# YTM32B1HA0 register map
Vendor: YTMicro; File version: 1.0
CPU: little endian, MPU, FPU, 2 interrupt priority bits
Registers are 32-bit, read-write, reset 0x0 unless marked. A register's access mark holds for its fields unless they carry their own. Offsets are from the block's base; [hi:lo] are bit positions; {n}, {i} and the like mark numbered series; 'fields as' and 'values as' point back to an identical list.

## ENET (part 9 of 10) — Ethernet Quality-of-Service
Base 0x401E4000; register names take the prefix ENET_
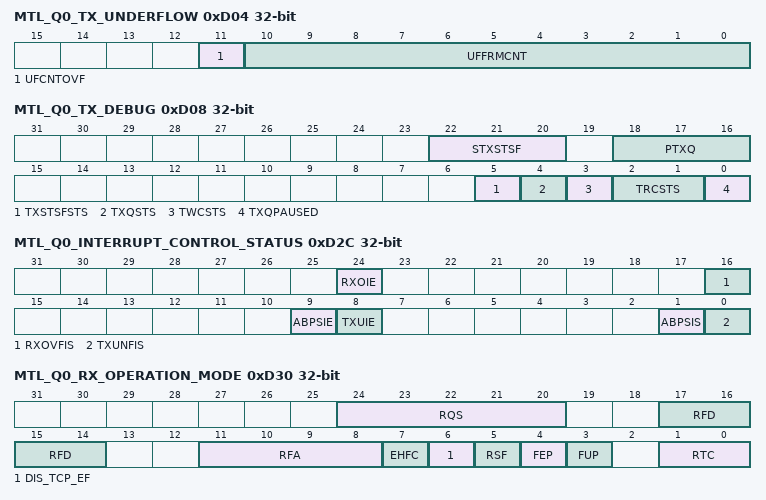
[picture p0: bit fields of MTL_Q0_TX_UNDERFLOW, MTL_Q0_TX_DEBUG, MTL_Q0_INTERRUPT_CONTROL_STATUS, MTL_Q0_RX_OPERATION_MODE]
0xD04 MTL_Q0_TX_UNDERFLOW — The Queue 0 Underflow Counter register contains the counter for packets aborted because of Transmit queue underflow and packets missed because of Receive queue packet flush
  [11] UFCNTOVF — This bit is set every time the Tx queue Underflow Packet Counter field overflows, that is, it has crossed the maximum count. In such a scenario, the overflow packet counter is reset to all-zeros and this bit indicates that the rollover happened. Access restriction applies. Clears on read. Self-set to 1 on internal event.
    0=Overflow not detected for Underflow Packet Counter; 1=Overflow detected for Underflow Packet Counter
  [10:0] UFFRMCNT — This field indicates the number of packets aborted by the controller because of Tx Queue Underflow. This counter is incremented each time the MAC aborts outgoing packet because of underflow. The counter is cleared when this register is read with mci_be_i[0] at 1'b1. Access restriction applies. Clears on read. Self-set to 1 on internal event.
0xD08 MTL_Q0_TX_DEBUG — The Queue 0 Transmit Debug register gives the debug status of various blocks related to the Transmit queue.
  [22:20] STXSTSF — This field indicates the current number of status in the Tx Status FIFO of this queue. When the DTXSTS bit of MTL_Operation_Mode register is set to 1, this field does not reflect the number of status words in Tx Status FIFO.
  [18:16] PTXQ — This field indicates the current number of packets in the Tx Queue. When the DTXSTS bit of MTL_Operation_Mode register is set to 1, this field does not reflect the number of packets in the Transmit queue.
  [5] TXSTSFSTS — When high, this bit indicates that the MTL Tx Status FIFO is full. Therefore, the MTL cannot accept any more packets for transmission.
    0=MTL Tx Status FIFO Full status is not detected; 1=MTL Tx Status FIFO Full status is detected
  [4] TXQSTS — When this bit is high, it indicates that the MTL Tx Queue is not empty and some data is left for transmission.
    0=MTL Tx Queue Not Empty status is not detected; 1=MTL Tx Queue Not Empty status is detected
  [3] TWCSTS — When high, this bit indicates that the MTL Tx Queue Write Controller is active, and it is transferring the data to the Tx Queue.
    0=MTL Tx Queue Write Controller status is not detected; 1=MTL Tx Queue Write Controller status is detected
  [2:1] TRCSTS — This field indicates the state of the Tx Queue Read Controller:
    0=Idle state; 1=Read state (transferring data to the MAC transmitter); 2=Waiting for pending Tx Status from the MAC transmitter; 3=Flushing the Tx queue because of the Packet Abort request from the MAC
  [0] TXQPAUSED — When this bit is high and the Rx flow control is enabled, it indicates that the Tx Queue is in the Pause condition (in the full-duplex only mode) because of the following: ■ Reception of the PFC packet for the priorities assigned to the Tx Queue when PFC is enabled ■ Reception of 802.3x Pause packet when PFC is disabled
    0=Transmit Queue in Pause status is not detected; 1=Transmit Queue in Pause status is detected
0xD14 MTL_Q0_TX_ETS_STATUS ro — The Queue n ETS Status register provides the average traffic transmitted in Queue n.
  [23:0] ABS rw — This field contains the average transmitted bits per slot. When the DCB operation is enabled for Queue 0, this field is computed over every 10 million bit times slot (4 ms in 2500 Mbps; 10 ms in 1000 Mbps; 100 ms in 100 Mbps). The maximum value is 0x989680.
0xD18 MTL_Q0_TX_QUANTUM_WEIGHT — The Queue n Quantum or Weights register contains the quantum value for Deficit Weighted Round Robin (DWRR), weights for the Weighted Round Robin (WRR), and Weighted Fair Queuing (WFQ) for Queue n.
  [20:0] ISCQW — When the DCB operation is enabled with DWRR algorithm for Queue 0 traffic, this field contains the quantum value in bytes to be added to credit during every queue scanning cycle. The maximum value is 0x1312D0 bytes. When DCB operation is enabled with WFQ algorithm for Queue 0 traffic, this field contains the weight for this queue. The maximum value is 0x3FFF where weight of 0 indicates 100% bandwidth. Bits[20:14] must be written to zero. The higher the programmed weights lesser the bandwidth allocated for the particular Transmit Queue. This is because the weights are used to compute the packet finish time (weights*packet_size). Lesser the finish time, higher the probability of the packet getting scheduled first and using more bandwidth. When DCB operation or generic queuing operation is enabled with WRR algorithm for Queue 0 traffic, this field contains the weight for this queue. The maximum value is 0x64. Bits [20:7] must be written to zero.
0xD2C MTL_Q0_INTERRUPT_CONTROL_STATUS — This register contains the interrupt enable and status bits for the queue 0 interrupts.
  [24] RXOIE — When this bit is set, the Receive Queue Overflow interrupt is enabled. When this bit is reset, the Receive Queue Overflow interrupt is disabled.
    0=Receive Queue Overflow Interrupt is disabled; 1=Receive Queue Overflow Interrupt is enabled
  [16] RXOVFIS — This bit indicates that the Receive Queue had an overflow while receiving the packet. If a partial packet is transferred to the application, the overflow status is set in RDES3[21]. This bit is cleared when the application writes 1 to this bit. Access restriction applies. Self-set to 1 on internal event. Setting 1 clears. Setting 0 has no effect.
    0=Receive Queue Overflow Interrupt Status not detected; 1=Receive Queue Overflow Interrupt Status detected
  [9] ABPSIE — When this bit is set, the MAC asserts the sbd_intr_o or mci_intr_o interrupt when the average bits per slot status is updated. When this bit is cleared, the interrupt is not asserted for such an event.
    0=Average Bits Per Slot Interrupt is disabled; 1=Average Bits Per Slot Interrupt is enabled
  [8] TXUIE — When this bit is set, the Transmit Queue Underflow interrupt is enabled. When this bit is reset, the Transmit Queue Underflow interrupt is disabled.
    0=Transmit Queue Underflow Interrupt Status is disabled; 1=Transmit Queue Underflow Interrupt Status is enabled
  [1] ABPSIS — When set, this bit indicates that the MAC has updated the ABS value. This bit is cleared when the application writes 1 to this bit. Access restriction applies. Self-set to 1 on internal event. Setting 1 clears. Setting 0 has no effect.
    0=Average Bits Per Slot Interrupt Status not detected; 1=Average Bits Per Slot Interrupt Status detected
  [0] TXUNFIS — This bit indicates that the Transmit Queue had an underflow while transmitting the packet. Transmission is suspended and an Underflow Error TDES3[2] is set. This bit is cleared when the application writes 1 to this bit. Access restriction applies. Self-set to 1 on internal event. Setting 1 clears. Setting 0 has no effect.
    0=Transmit Queue Underflow Interrupt Status not detected; 1=Transmit Queue Underflow Interrupt Status detected
0xD30 MTL_Q0_RX_OPERATION_MODE — The Queue 0 Receive Operation Mode register establishes the Receive queue operating modes and command. The RFA and RFD fields are not backward compatible with the RFA and RFD fields of 4.00a release
  [24:20] RQS — This field indicates the size of the allocated Receive queues in blocks of 256 bytes. The RQS field is read-write only if the number of Rx Queues more than one, the reset value is 0x0 and indicates size of 256 bytes. When the number of Rx Queues is one, the field is read-only and the configured RX FIFO size in blocks of 256 bytes is reflected in the reset value. The width of this field depends on the Rx memory size selected in your configuration. For example, if the memory size is 2048, the width of this field is 3 bits: LOG2(2048/256) = LOG2(8) = 3 bits
  [17:14] RFD — These bits control the threshold (fill-level of Rx queue) at which the flow control is de-asserted after activation: ■ 0: Full minus 1 KB, that is, FULL 1 KB ■ 1: Full minus 1.5 KB, that is, FULL 1.5 KB ■ 2: Full minus 2 KB, that is, FULL 2 KB ■ 3: Full minus 2.5 KB, that is, FULL 2.5 KB ■ ... ■ 62: Full minus 32 KB, that is, FULL 32 KB ■ 63: Full minus 32.5 KB, that is, FULL 32.5 KB The de-assertion is effective only after flow control is asserted. Note: The value must be programmed in such a way to make sure that the threshold is a positive number. When the EHFC is set high, these values are applicable only when the Rx queue size determined by the RQS field of this register, is equal to or greater than 4 KB. For a given queue size, the values ranges between 0 and the encoding for FULL minus (QSIZE - 0.5 KB) and all other values are illegal. Here the term FULL and QSIZE refers to the queue size determined by the RQS field of this register. The width of this field depends on RX FIFO size selected during the configuration. Remaining bits are reserved and read only.
  [11:8] RFA — These bits control the threshold (fill-level of Rx queue) at which the flow control is activated: For more information on encoding for this field, see RFD.
  [7] EHFC — When this bit is set, the flow control signal operation, based on the fill-level of Rx queue, is enabled. When reset, the flow control operation is disabled.
    0=Hardware Flow Control is disabled; 1=Hardware Flow Control is enabled
  [6] DIS_TCP_EF — When this bit is set, the MAC does not drop the packets which only have the errors detected by the Receive Checksum Offload engine. Such packets have errors only in the encapsulated payload. There are no errors (including FCS error) in the Ethernet packet received by the MAC. When this bit is reset, all error packets are dropped if the FEP bit is reset.
    0=Dropping of TCP/IP Checksum Error Packets is enabled; 1=Dropping of TCP/IP Checksum Error Packets is disabled
  [5] RSF — When this bit is set, the DWC_ether_qos reads a packet from the Rx queue only after the complete packet has been written to it, ignoring the RTC field of this register. When this bit is reset, the Rx queue operates in the Threshold (cut-through) mode, subject to the threshold specified by the RTC field of this register.
    0=Receive Queue Store and Forward is disabled; 1=Receive Queue Store and Forward is enabled
  [4] FEP — When this bit is reset, the Rx queue drops packets with error status (CRC error, GMII_ER, watchdog timeout, or overflow). However, if the start byte (write) pointer of a packet is already transferred to the read controller side (in Threshold mode), the packet is not dropped. When this bit is set, all packets except the runt error packets are forwarded to the application or DMA. If the RSF bit is set and the Rx queue overflows when a partial packet is written, the packet is dropped irrespective of the setting of this bit. However, if the RSF bit is reset and the Rx queue overflows when a partial packet is written, a partial packet may be forwarded to the application or DMA.
    0=Forward Error Packets is disabled; 1=Forward Error Packets is enabled
  [3] FUP — When this bit is set, the Rx queue forwards the undersized good packets (packets with no error and length less than 64 bytes), including pad-bytes and CRC. When this bit is reset, the Rx queue drops all packets of less than 64 bytes, unless a packet is already transferred because of the lower value of Rx Threshold, for example, RTC = 01.
    0=Forward Undersized Good Packets is disabled; 1=Forward Undersized Good Packets is enabled
  [1:0] RTC — These bits control the threshold level of the MTL Rx queue (in bytes): The received packet is transferred to the application or DMA when the packet size within the MTL Rx queue is larger than the threshold. In addition, full packets with length less than the threshold are automatically transferred. This field is valid only when the RSF bit is zero. This field is ignored when the RSF bit is set to 1.
    0=64; 1=32; 2=96; 3=128
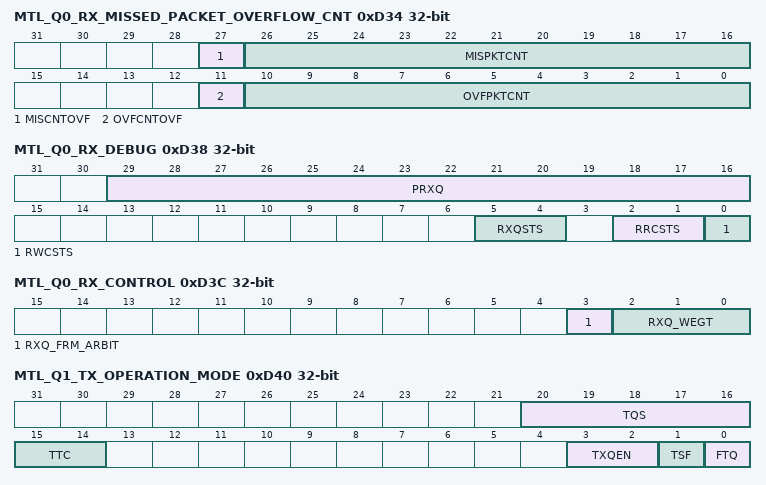
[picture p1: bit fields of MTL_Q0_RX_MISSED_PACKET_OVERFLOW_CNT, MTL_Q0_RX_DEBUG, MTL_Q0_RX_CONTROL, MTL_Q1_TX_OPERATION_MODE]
0xD34 MTL_Q0_RX_MISSED_PACKET_OVERFLOW_CNT — The Queue 0 Missed Packet and Overflow Counter register contains the counter for packets missed because of Receive queue packet flush and packets discarded because of Receive queue overflow.
  [27] MISCNTOVF — When set, this bit indicates that the Rx Queue Missed Packet Counter crossed the maximum limit. Access restriction applies. Clears on read. Self-set to 1 on internal event.
    0=Missed Packet Counter overflow not detected; 1=Missed Packet Counter overflow detected
  [26:16] MISPKTCNT — This field indicates the number of packets missed by the DWC_ether_qos because the application asserted ari_pkt_flush_i[] for this queue. This counter is incremented each time the application issues ari_pkt_flush_i[] for this queue. This counter is reset when this register is read with mci_be_i[0] at 1b1. In EQOS-DMA, EQOS-AXI, and EQOS-AHB configurations, This counter is incremented by 1 when the DMA discards the packet because of buffer unavailability. Access restriction applies. Clears on read. Self-set to 1 on internal event.
  [11] OVFCNTOVF — When set, this bit indicates that the Rx Queue Overflow Packet Counter field crossed the maximum limit. Access restriction applies. Clears on read. Self-set to 1 on internal event.
    0=Overflow Counter overflow not detected; 1=Overflow Counter overflow detected
  [10:0] OVFPKTCNT — This field indicates the number of packets discarded by the DWC_ether_qos because of Receive queue overflow. This counter is incremented each time the DWC_ether_qos discards an incoming packet because of overflow. This counter is reset when this register is read with mci_be_i[0] at 1'b1. Access restriction applies. Clears on read. Self-set to 1 on internal event.
0xD38 MTL_Q0_RX_DEBUG ro — The Queue 0 Receive Debug register gives the debug status of various blocks related to the Receive queue.
  [29:16] PRXQ rw — This field indicates the current number of packets in the Rx Queue. The theoretical maximum value for this field is 256KB/16B = 16K Packets, that is, Max_Queue_Size/Min_Packet_Size.
  [5:4] RXQSTS rw — This field gives the status of the fill-level of the Rx Queue:
    0=Rx Queue empty; 1=Rx Queue fill-level below flow-control deactivate threshold; 2=Rx Queue fill-level above flow-control activate threshold; 3=Rx Queue full
  [2:1] RRCSTS rw — This field gives the state of the Rx queue Read controller:
    0=Idle state; 1=Reading packet data; 2=Reading packet status (or timestamp); 3=Flushing the packet data and status
  [0] RWCSTS rw — When high, this bit indicates that the MTL Rx queue Write controller is active, and it is transferring a received packet to the Rx Queue.
    0=MTL Rx Queue Write Controller Active Status not detected; 1=MTL Rx Queue Write Controller Active Status detected
0xD3C MTL_Q0_RX_CONTROL — The Queue Receive Control register controls the receive arbitration and passing of received packets to the application.
  [3] RXQ_FRM_ARBIT — When this bit is set, the DWC_ether_qos drives the packet data to the ARI interface such that the entire packet data of currently-selected queue is transmitted before switching to other queue. When this bit is reset, the DWC_ether_qos drives the packet data to the ARI interface such that the following amount of data of currently-selected queue is transmitted before switching to other queue: ■ PBL amount of data (indicated by ari_qN_pbl_i[]) or ■ Complete data of a packet The status and the timestamp are not a part of the PBL data. Therefore, the DWC_ether_qos drives the complete status (including timestamp status) during first PBL request for the packet (in store-and-forward mode) or the last PBL request for the packet (in Threshold mode).
    0=Receive Queue Packet Arbitration is disabled; 1=Receive Queue Packet Arbitration is enabled
  [2:0] RXQ_WEGT — This field indicates the weight assigned to the Rx Queue 0. The weight is used as the number of continuous PBL or packets requests (depending on the RXQ_FRM_ARBIT) allocated to the queue in one arbitration cycle.
0xD40 MTL_Q1_TX_OPERATION_MODE — The Queue n Transmit Operation Mode register establishes the Transmit queue operating modes and commands.
  [20:16] TQS — This field indicates the size of the allocated Transmit queues in blocks of 256 bytes. The TQS field is read-write only if the number of Tx Queues more than one, the reset value is 0x0 and indicates size of 256 bytes. When the number of Tx Queues is one, the field is read-only and the configured TX FIFO size in blocks of 256 bytes is reflected in the reset value. The width of this field depends on the Tx memory size selected in your configuration. For example, if the memory size is 2048, the width of this field is 3 bits: LOG2(2048/256) = LOG2(8) = 3 bits
  [15:14] TTC — These bits control the threshold level of the MTL Tx Queue. The transmission starts when the packet size within the MTL Tx Queue is larger than the threshold. In addition, full packets with length less than the threshold are also transmitted. These bits are used only when the TSF bit is reset.
    0=32; 1=64; 2=96; 3=128; 4=192; 5=256; 6=384; 7=512
  [3:2] TXQEN — This field is used to enable/disable the transmit queue 0. ■ 2'b00: Not enabled ■ 2'b01: Reserved ■ 2'b10: Enabled ■ 2'b11: Reserved This field is Read Only in Single Queue configurations and Read Write in Multiple Queue configurations. Note: In multiple Tx queues configuration, all the queues are disabled by default. Enable the Tx queue by programming this field.
    0=Not enabled; 1=Enable in AV mode (Reserved in non-AV); 2=Enabled
  [1] TSF — When this bit is set, the transmission starts when a full packet resides in the MTL Tx queue. When this bit is set, the TTC values specified in Bits[6:4] of this register are ignored. This bit should be changed only when the transmission is stopped.
    0=Transmit Store and Forward is disabled; 1=Transmit Store and Forward is enabled
  [0] FTQ — When this bit is set, the Tx queue controller logic is reset to its default values. Therefore, all the data in the Tx queue is lost or flushed. This bit is internally reset when the flushing operation is complete. Until this bit is reset, you should not write to the MTL_TxQ1_Operation_Mode register. The data which is already accepted by the MAC transmitter is not flushed. It is scheduled for transmission and results in underflow and runt packet transmission. Note: The flush operation is complete only when the Tx queue is empty and the application has accepted the pending Tx Status of all transmitted packets. To complete this flush operation, the PHY Tx clock (clk_tx_i) should be active. Access restriction applies. Setting 1 sets. Self-cleared. Setting 0 has no effect.
    0=Flush Transmit Queue is disabled; 1=Flush Transmit Queue is enabled
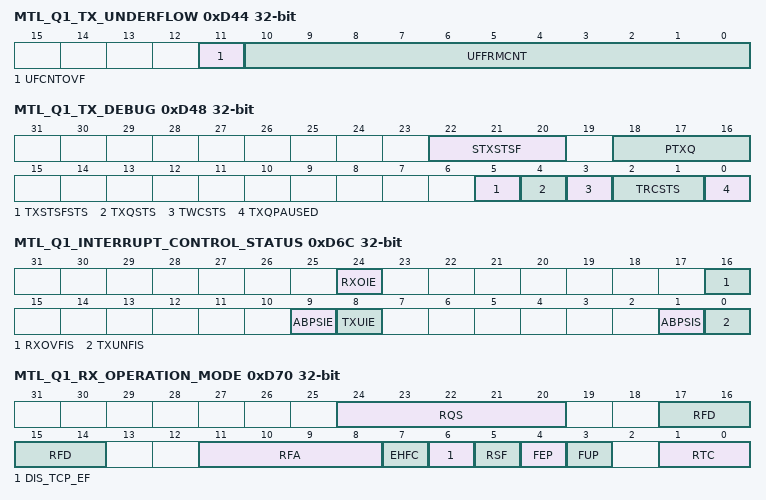
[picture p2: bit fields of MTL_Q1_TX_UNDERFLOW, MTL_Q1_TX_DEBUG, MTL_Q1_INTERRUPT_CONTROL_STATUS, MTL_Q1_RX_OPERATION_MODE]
0xD44 MTL_Q1_TX_UNDERFLOW — The Queue 0 Underflow Counter register contains the counter for packets aborted because of Transmit queue underflow and packets missed because of Receive queue packet flush
  fields as MTL_Q0_TX_UNDERFLOW
0xD48 MTL_Q1_TX_DEBUG — The Queue 0 Transmit Debug register gives the debug status of various blocks related to the Transmit queue.
  fields as MTL_Q0_TX_DEBUG
0xD54 MTL_Q1_TX_ETS_STATUS ro — The Queue n ETS Status register provides the average traffic transmitted in Queue n.
  fields as MTL_Q0_TX_ETS_STATUS
0xD58 MTL_Q1_TX_QUANTUM_WEIGHT — The Queue n Quantum or Weights register contains the quantum value for Deficit Weighted Round Robin (DWRR), weights for the Weighted Round Robin (WRR), and Weighted Fair Queuing (WFQ) for Queue n.
  fields as MTL_Q0_TX_QUANTUM_WEIGHT
0xD6C MTL_Q1_INTERRUPT_CONTROL_STATUS — This register contains the interrupt enable and status bits for the queue 0 interrupts.
  fields as MTL_Q0_INTERRUPT_CONTROL_STATUS
0xD70 MTL_Q1_RX_OPERATION_MODE — The Queue 0 Receive Operation Mode register establishes the Receive queue operating modes and command. The RFA and RFD fields are not backward compatible with the RFA and RFD fields of 4.00a release
  fields as MTL_Q0_RX_OPERATION_MODE
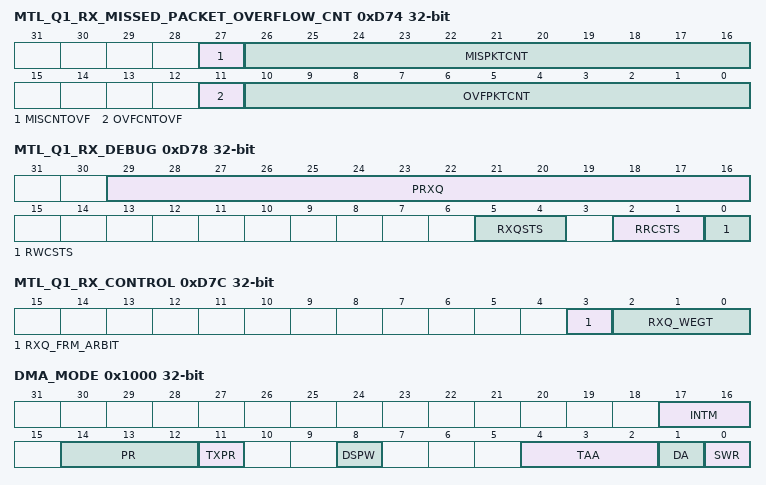
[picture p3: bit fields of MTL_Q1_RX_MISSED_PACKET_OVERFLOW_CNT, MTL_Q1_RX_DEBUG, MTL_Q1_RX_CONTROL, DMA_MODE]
0xD74 MTL_Q1_RX_MISSED_PACKET_OVERFLOW_CNT — The Queue 0 Missed Packet and Overflow Counter register contains the counter for packets missed because of Receive queue packet flush and packets discarded because of Receive queue overflow.
  fields as MTL_Q0_RX_MISSED_PACKET_OVERFLOW_CNT
0xD78 MTL_Q1_RX_DEBUG ro — The Queue 0 Receive Debug register gives the debug status of various blocks related to the Receive queue.
  fields as MTL_Q0_RX_DEBUG
0xD7C MTL_Q1_RX_CONTROL — The Queue Receive Control register controls the receive arbitration and passing of received packets to the application.
  fields as MTL_Q0_RX_CONTROL
0x1000 DMA_MODE — The Bus Mode register establishes the bus operating modes for the DMA.
  [17:16] INTM — This field defines the interrupt mode of DWC_ether_qos. The behavior of the following outputs changes depending on the following settings: ■ sbd_perch_tx_intr_o[] (Transmit Per Channel Interrupt) ■ sbd_perch_rx_intr_o[] (Receive Per Channel Interrupt) ■ sbd_intr_o (Common Interrupt) It also changes the behavior of the RI/TI bits in the DMA_CH0_Status. ■ 00: sbd_perch_* are pulse signals for each TX/RX packet transfer completion events (irrespective of whether corre- sponding interrupts are enabled) for which IOC bits are enabled in descriptor. sbd_intr_o is also asserted when corresponding interrupts are enabled and cleared only when software clears the corresponding RI/TI status bits. ■ 01: sbd_perch_* are level signals asserted on TX/RX packet transfer completion event when corresponding interrupts are enabled and de-asserted when the software clears the corresponding RI/TI status bits. The sbd_intr_o is not asserted for these TX/RX packet transfer completion events. ■ 10: sbd_perch_* are level signals asserted on TX/RX packet transfer completion event when corresponding interrupts are enabled and de-asserted when the software clears the corresponding RI/TI status bits. However, the signal is asserted again if the same event occurred again before it was cleared. The sbd_intr_o is not asserted for these TX/RX packet transfer completion events. ■ 11: Reserved For more details please refer Table "DWC_ether_qos Transfer Complete Interrupt Behavior".
    0=See above description; 1=See above description; 2=See above description
  [14:12] PR — These bits control the priority ratio in weighted round-robin arbitration between the Rx DMA and Tx DMA. These bits are valid only when the DA bit is reset. The priority ratio is Rx:Tx or Tx:Rx depending on whether the TXPR bit is reset or set.
    0=61; 1=121; 2=181; 3=241; 4=301; 5=361; 6=421; 7=481
  [11] TXPR — When set, this bit indicates that the Tx DMA has higher priority than the Rx DMA during arbitration for the system-side bus.
    0=Transmit Priority is disabled; 1=Transmit Priority is enabled
  [8] DSPW — When this bit is set to 0, the descriptor writes are always non-posted. When this bit is set to 1, the descriptor writes are non-posted only when IOC (Interrupt on completion) is set in last descriptor, otherwise the descriptor writes are always posted.
    0=Descriptor Posted Write is disabled; 1=Descriptor Posted Write is enabled
  [4:2] TAA — This field is used to select the arbitration algorithm for the Transmit side when multiple Tx DMAs are selected.
    0=Fixed priority (Channel 0 has the lowest priority and the last channel has the highest priority); 1=Weighted Strict Priority (WSP); 2=Weighted Round Robin (WRR)
  [1] DA — This bit specifies the arbitration scheme between the Transmit and Receive paths of all channels: ■ 0: Weighted Round-Robin with Rx:Tx or Tx:Rx The priority between the paths is according to the priority specified in Bits[14:12] and the priority weight is specified in the TXPR bit. ■ 1: Fixed Priority The Tx path has priority over the Rx path when the TXPR bit is set. Otherwise, the Rx path has priority over the Tx path.
    0=Weighted Round-Robin with Rx:Tx or Tx:Rx; 1=Fixed Priority
  [0] SWR — When this bit is set, the MAC and the DMA controller reset the logic and all internal registers of the DMA, MTL, and MAC. This bit is automatically cleared after the reset operation is complete in all DWC_ether_qos clock domains. Before reprogramming any DWC_ether_qos register, a value of zero should be read in this bit. This bit must be read at least 4 CSR clock cycles after it is written to 1. Note: The reset operation is complete only when all resets in all active clock domains are de-asserted. Therefore, it is essential that all PHY inputs clocks (applicable for the selected PHY interface) are present for software reset completion. The time to complete the software reset operation depends on the frequency of the slowest active clock. Access restriction applies. Setting 1 sets. Self-cleared. Setting 0 has no effect.
    0=Software Reset is disabled; 1=Software Reset is enabled
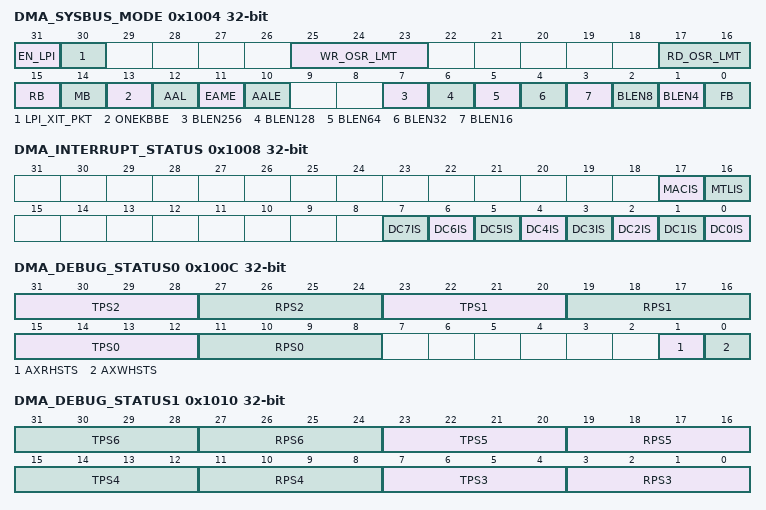
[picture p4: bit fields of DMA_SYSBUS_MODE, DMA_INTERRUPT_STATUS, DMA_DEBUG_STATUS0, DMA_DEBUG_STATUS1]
0x1004 DMA_SYSBUS_MODE — The System Bus mode register controls the behavior of the AHB or AXI master. It mainly controls burst splitting and number of outstanding requests.
  [31] EN_LPI — When set to 1, this bit enables the LPI mode supported by the EQOS-AXI configuration and accepts the LPI request from the AXI System Clock controller. When set to 0, this bit disables the LPI mode and always denies the LPI request from the AXI System Clock controller.
    0=Low Power Interface (LPI) is disabled; 1=Low Power Interface (LPI) is enabled
  [30] LPI_XIT_PKT — When set to 1, this bit enables the AXI master to come out of the LPI mode only when the magic packet or remote wake-up packet is received. When set to 0, this bit enables the AXI master to come out of the LPI mode when any packet is received.
    0=Unlock on Magic Packet or Remote Wake-Up Packet is disabled; 1=Unlock on Magic Packet or Remote Wake-Up Packet is enabled
  [25:23] WR_OSR_LMT — This value limits the maximum outstanding request on the AXI write interface. Maximum outstanding requests = WR_OSR_LMT + 1 Note: ■ Bit 26 is reserved if DWC_ETHER_QOS_AXI_MAX- _WR_REQ = 4 ■ Bit 27 is reserved if DWC_ETHER_QOS_AXI_MAX- _WR_REQ!= 16
  [17:16] RD_OSR_LMT — This value limits the maximum outstanding request on the AXI read interface. Maximum outstanding requests = RD_OSR_LMT + 1
  [15] RB — When this bit is set high and the AHB master gets SPLIT, RETRY, or Early Burst Termination (EBT) response, the AHB master interface rebuilds the pending beats of any initiated burst transfer with INCRx and SINGLE transfers. By default, the AHB master interface rebuilds pending beats of an EBT with an unspecified (INCR) burst.
    0=Rebuild INCRx Burst is disabled; 1=Rebuild INCRx Burst is enabled
  [14] MB — When this bit is set high and the FB bit is low, the AHB master performs undefined bursts transfers (INCR) for burst length of 16 or more. For burst length of 16 or less, the AHB master performs fixed burst transfers (INCRx and SINGLE).
    0=Mixed Burst is disabled; 1=Mixed Burst is enabled
  [13] ONEKBBE — When set, the burst transfers performed by the EQOS-AXI master do not cross 1 KB boundary. When reset, the burst transfers performed by the EQOS-AXI master do not cross 4 KB boundary.
    0=1 KB Boundary Crossing for the EQOS-AXI Master Beats is disabled; 1=1 KB Boundary Crossing for the EQOS-AXI Master Beats is enabled
  [12] AAL — When this bit is set to 1, the EQOS-AXI or EQOS-AHB master performs address-aligned burst transfers on Read and Write channels.
    0=Address-Aligned Beats is disabled; 1=Address-Aligned Beats is enabled
  [11] EAME — When this bit is set to 1, the DMA master enables the enhanced address mode (40-bit or 48-bit addressing mode). In this mode, the DMA engine uses either the 40- or 48-bit address, depending on the configuration.
    0=Enhanced Address Mode is disabled; 1=Enhanced Address Mode is enabled
  [10] AALE — When set to 1, enables the AXI master to enter into LPI state when there is no activity in the DWC_ether_qos for number of system clock cycles programmed in the LPIEI field of AXI_LPI_Entry_Interval register.
    0=Automatic AXI LPI is disabled; 1=Automatic AXI LPI is enabled
  [7] BLEN256 — When this bit is set to 1, the EQOS-AXI master can select a burst length of 256 on the AXI interface.
    0=No effect; 1=AXI Burst Length 256
  [6] BLEN128 — When this bit is set to 1, the EQOS-AXI master can select a burst length of 128 on the AXI interface.
    0=No effect; 1=AXI Burst Length 128
  [5] BLEN64 — When this bit is set to 1, the EQOS-AXI master can select a burst length of 64 on the AXI interface.
    0=No effect; 1=AXI Burst Length 64
  [4] BLEN32 — When this bit is set to 1, the EQOS-AXI master can select a burst length of 32 on the AXI interface.
    0=No effect; 1=AXI Burst Length 32
  [3] BLEN16 — When this bit is set to 1, the EQOS-AXI master can select a burst length of 16 on the AXI interface.
    0=No effect; 1=AXI Burst Length 16
  [2] BLEN8 — When this bit is set to 1, the EQOS-AXI master can select a burst length of 8 on the AXI interface.
    0=No effect; 1=AXI Burst Length 8
  [1] BLEN4 — When this bit is set to 1, the EQOS-AXI master can select a burst length of 4 on the AXI interface.
    0=No effect; 1=AXI Burst Length 4
  [0] FB — For EQOS-AXI Configurations: When this bit is set to 1, the EQOS-AXI master initiates burst transfers of specified lengths as given below. ■ Burst transfers of fixed burst lengths as indicated by the BLEN256, BLEN128, BLEN64, BLEN32, BLEN16, BLEN8, or BLEN4 field ■ Burst transfers of length 1 When this bit is set to 0, the EQOS-AXI master initiates burst transfers that are equal to or less than the maximum allowed burst length programmed in Bits[7:1]. For EQOS-AHB Configurations: When this bit is set to 1, the AHB master initiates burst transfers of specified length (INCRx or SINGLE). When this bit is set to 0, the AHB master initiates transfers of unspecified length (INCR) or SINGLE transfers. For EQOS-DMA Configurations: The value of this bit is driven on the mdc_burst_count_o output signal.
    0=Fixed Burst Length is disabled; 1=Fixed Burst Length is enabled
0x1008 DMA_INTERRUPT_STATUS ro — The application reads this Interrupt Status register during interrupt service routine or polling to determine the interrupt status of DMA channels, MTL queues, and the MAC.
  [17] MACIS rw — This bit indicates an interrupt event in the MAC. To reset this bit to 1'b0, the software must read the corresponding register in the MAC to get the exact cause of the interrupt and clear its source.
    0=MAC Interrupt Status not detected; 1=MAC Interrupt Status detected
  [16] MTLIS rw — This bit indicates an interrupt event in the MTL. To reset this bit to 1'b0, the software must read the corresponding register in the MTL to get the exact cause of the interrupt and clear its source.
    0=MTL Interrupt Status not detected; 1=MTL Interrupt Status detected
  [n] DC{n}IS rw (n=0..7) — This bit indicates an interrupt event in DMA Channel {n}. To reset this bit to 1'b0, the software must read the corresponding register in DMA Channel {n} to get the exact cause of the interrupt and clear its source.
    0=DMA Channel {n} Interrupt Status not detected; 1=DMA Channel {n} Interrupt Status detected
0x100C DMA_DEBUG_STATUS0 ro — The Debug Status 0 register gives the Receive and Transmit process status for DMA Channel 0-Channel 2 for debugging purpose.
  [31:28] TPS2 rw — This field indicates the Tx DMA FSM state for Channel 2. The MSB of this field always returns 0. This field does not generate an interrupt.
    0=Stopped (Reset or Stop Transmit Command issued); 1=Running (Fetching Tx Transfer Descriptor); 2=Running (Waiting for status); 3=Running (Reading Data from system memory buffer and queuing it to the Tx buffer (Tx FIFO)); 4=Timestamp write state; 5=Reserved for future use; 6=Suspended (Tx Descriptor Unavailable or Tx Buffer Underflow); 7=Running (Closing Tx Descriptor)
  [27:24] RPS2 rw — This field indicates the Rx DMA FSM state for Channel 2. The MSB of this field always returns 0. This field does not generate an interrupt.
    0=Stopped (Reset or Stop Receive Command issued); 1=Running (Fetching Rx Transfer Descriptor); 2=Reserved for future use; 3=Running (Waiting for Rx packet); 4=Suspended (Rx Descriptor Unavailable); 5=Running (Closing the Rx Descriptor); 6=Timestamp write state; 7=Running (Transferring the received packet data from the Rx buffer to the system memory)
  [23:20] TPS1 rw — This field indicates the Tx DMA FSM state for Channel 1. The MSB of this field always returns 0. This field does not generate an interrupt.
    values as TPS2
  [19:16] RPS1 rw — This field indicates the Rx DMA FSM state for Channel 1. The MSB of this field always returns 0. This field does not generate an interrupt.
    values as RPS2
  [15:12] TPS0 rw — This field indicates the Tx DMA FSM state for Channel 0. The MSB of this field always returns 0. This field does not generate an interrupt.
    values as TPS2
  [11:8] RPS0 rw — This field indicates the Rx DMA FSM state for Channel 0. The MSB of this field always returns 0. This field does not generate an interrupt.
    values as RPS2
  [1] AXRHSTS rw — When high, this bit indicates that the read channel of the AXI master is active, and it is transferring the data.
    0=AXI Master Read Channel Status not detected; 1=AXI Master Read Channel Status detected
  [0] AXWHSTS rw — EQOS-AXI Configuration: When high, this bit indicates that the write channel of the AXI master is active, and it is transferring data. EQOS-AHB Configuration: When high, this bit indicates that the AHB master FSMs are in the non-idle state.
    0=AXI Master Write Channel or AHB Master Status not detected; 1=AXI Master Write Channel or AHB Master Status detected
0x1010 DMA_DEBUG_STATUS1 ro — The Debug Status1 register gives the Receive and Transmit process status for DMA Channel 3-Channel 6.
  [8n-17:8n-20] TPS{n} rw (n=3..6) — This field indicates the Tx DMA FSM state for Channel {n}. The MSB of this field always returns 0. This field does not generate an interrupt.
    values as DMA_DEBUG_STATUS0.TPS2
  [8n-21:8n-24] RPS{n} rw (n=3..6) — This field indicates the Rx DMA FSM state for Channel {n}. The MSB of this field always returns 0. This field does not generate an interrupt.
    values as DMA_DEBUG_STATUS0.RPS2
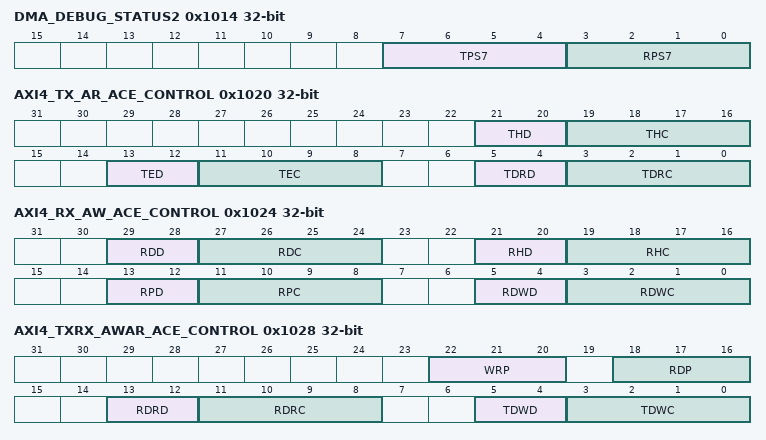
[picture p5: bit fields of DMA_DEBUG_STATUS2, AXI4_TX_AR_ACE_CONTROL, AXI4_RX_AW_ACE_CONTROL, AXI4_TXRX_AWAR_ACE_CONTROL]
0x1014 DMA_DEBUG_STATUS2 ro — The Debug Status Register 2 gives the Receive and Transmit process status for DMA Channel 7.
  [7:4] TPS7 rw — This field indicates the Tx DMA FSM state for Channel 7. The MSB of this field always returns 0. This field does not generate an interrupt.
    values as DMA_DEBUG_STATUS0.TPS2
  [3:0] RPS7 rw — This field indicates the Rx DMA FSM state for Channel 7. The MSB of this field always returns 0. This field does not generate an interrupt.
    values as DMA_DEBUG_STATUS0.RPS2
0x1020 AXI4_TX_AR_ACE_CONTROL — This register controls the AXI4 Tx AR ACE attributes.
  [21:20] THD — When TSO is NOT enabled, This field is used to drive ardomain_o[1:0] signal when Transmit DMA is accessing First Buffer of the Packet (First valid buffer with FD being set in the TDES3 of the Descriptor). When TSO is enabled, This field is used to drive ardomain_o[1:0] signal when the Transmit DMA is accessing the TSO Header data.
  [19:16] THC — When TSO is NOT enabled, This field is used to drive arcache_o[3:0] signal when Transmit DMA is accessing First Buffer of the Packet (First valid buffer with FD being set in the TDES3 of the Descriptor).. When TSO is enabled, This field is used to drive arcache_o[3:0] signal when the Transmit DMA is accessing the TSO Header data.
  [13:12] TED — When TSO is NOT enabled, This field is used to drive ardomain_o[1:0] signal when Transmit DMA is accessing the extended buffers (when packet is distributed across multiple buffers). When TSO is enabled, This field is used to drive ardomain_o[1:0] signal when the Transmit DMA is accessing the TSO payload data.
  [11:8] TEC — When TSO is NOT enabled, This field is used to drive arcache_o[3:0] signal when Transmit DMA is accessing the extended buffers (when packet is distributed across multiple buffers). When TSO is enabled, This field is used to drive arcache_o[3:0] signal when the Transmit DMA is accessing the TSO payload data.
  [5:4] TDRD — This field is used to drive ardomain_o[1:0] signal when Transmit DMA engines access the Descriptor.
  [3:0] TDRC — This field is used to drive arcache_o[3:0] signal when Transmit DMA engines access the Descriptor.
0x1024 AXI4_RX_AW_ACE_CONTROL — This register is used to control the AXI4 Cache Coherency Signals for write transactions by all the Receive DMA channels. The following signals of the AXI4 interface are driven with different values as programmed for corresponding type (descriptor, buffer1, buffer2) of access. ❑ awcache_m_o[3:0] ❑ awdomain_m_o[1:0]
  [29:28] RDD — This field is used to drive awdomain_o[1:0] signal when Receive DMA engines access the Descriptor.
  [27:24] RDC — This field is used to drive awcache_o[3:0] signal when Receive DMA is accessing the Buffer when Header and payload are NOT separated.
  [21:20] RHD — This field is used to drive awdomain_o[1:0] and signal when Receive DMA is accessing the header Buffer when Header and payload are separated.
  [19:16] RHC — This field is used to drive awcache_o[3:0] and signal when Receive DMA is accessing the header Buffer when Header and payload are separated.
  [13:12] RPD — This field is used to drive awdomain_o[1:0] signal when Receive DMA is accessing the Payload Buffer when Header and payload are separated.
  [11:8] RPC — This field is used to drive awcache_o[3:0] signal when Receive DMA is accessing the Payload Buffer when Header and payload are separated.
  [5:4] RDWD — This field is used to drive awdomain_o[1:0] signal when Receive DMA accesses the Descriptor.
  [3:0] RDWC — This field is used to drive awcache_o[3:0] signal when Receive DMA accesses the Descriptor.
0x1028 AXI4_TXRX_AWAR_ACE_CONTROL — This register is used to control the AXI4 Cache Coherency Signals for Descriptor write transactions by all the TxDMA channels and Descriptor read transactions by all the RxDMA channels. It also controls the values to be driven on awprot_m_o and arprot_m_o.
  [22:20] WRP — This field is used to drive awprot_m_o[2:0] signal on the AXI Write Channel.
  [18:16] RDP — This field is used to drive arprot_m_o[2:0] signal during all read requests.
  [13:12] RDRD — This field is used to drive ardomain_o[1:0] signal when Receive DMA engines read the Descriptor.
  [11:8] RDRC — This field is used to drive arcache_o[3:0] signal when Receive DMA engines read the Descriptor.
  [5:4] TDWD — This field is used to drive awdomain_o[1:0] signal when Transmit DMA write to the Descriptor.
  [3:0] TDWC — This field is used to drive awcache_o[3:0] signal when Transmit DMA writes to the Descriptor.
0x1040 AXI_LPI_ENTRY_INTERVAL — This register is used to control the AXI LPI entry interval.
  [3:0] LPIEI — Contains the number of system clock cycles, multiplied by 64, to wait for an activity in the DWC_ether_qos to enter into the AXI low power state 0 indicates 64 clock cycles
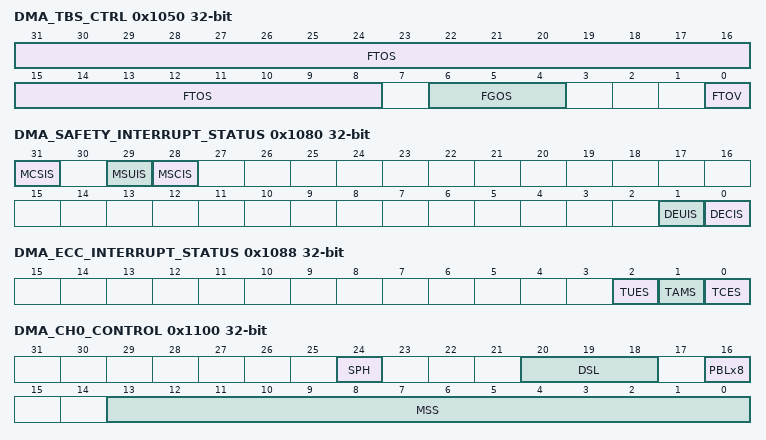
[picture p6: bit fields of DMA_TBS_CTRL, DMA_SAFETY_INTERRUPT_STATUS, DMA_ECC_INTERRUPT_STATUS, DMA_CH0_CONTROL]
0x1050 DMA_TBS_CTRL — This register is used to control the TBS attributes.
  [31:8] FTOS — The value in units of 256 nanoseconds, that has to be deducted from the Launch time to compute the Fetch Time. Max value: 999,999,999 ns, additionally should be smaller than CTR-1 value when ESTM mode is set since this value is a modulo CTR value.
  [6:4] FGOS — The number GSN slots that must be deducted from the Launch GSN to compute the Fetch GSN. Value valid only when FTOV is set.
  [0] FTOV — When set indicates the FTOS field is valid. When not set, indicates the Fetch Offset is not valid and the DMA engine can fetch the frames from host memory without any time restrictions.
    0=Fetch Time Offset is invalid; 1=Fetch Time Offset is invalid
0x1080 DMA_SAFETY_INTERRUPT_STATUS ro — This register indicates summary (whether error occured in DMA/MTL/MAC and correctable/uncorrectable) of the Automotive Safety related error interrupts.
  [31] MCSIS rw — Indicates a uncorrectable Safety related Interrupt is set in the MAC module. MAC_DPP_FSM_Interrupt_Status register should be read when this bit is set, to get the cause of the Safety Interrupt in MAC.
    0=MAC Safety Uncorrectable Interrupt Status not detected; 1=MAC Safety Uncorrectable Interrupt Status detected
  [29] MSUIS rw — This bit indicates an uncorrectable error interrupt event in MTL. To get exact cause of the interrupt the software should read the MTL_Safety_Interrupt_Status register.
    0=MTL Safety Uncorrectable error Interrupt Status not detected; 1=MTL Safety Uncorrectable error Interrupt Status detected
  [28] MSCIS rw — This bit indicates a correctable error interrupt event in MTL. To get exact cause of the interrupt the software should read the MTL_Safety_Interrupt_Status register.
    0=MTL Safety Correctable error Interrupt Status not detected; 1=MTL Safety Correctable error Interrupt Status not detected
  [1] DEUIS rw — This bit indicates an interrupt event in the DMA ECC safety feature. To get the exact cause of the interrupt the application should read the DMA_ECC_Interrupt_Status register.
    0=DMA ECC Uncorrectable error Interrupt Status not detected; 1=DMA ECC Uncorrectable error Interrupt Status detected
  [0] DECIS rw — This bit indicates an interrupt event in the DMA ECC safety feature. To get the exact cause of the interrupt the application should read the DMA_ECC_Interrupt_Status register.
    0=DMA ECC Correctable error Interrupt Status not detected; 1=DMA ECC Correctable error Interrupt Status detected
0x1084 DMA_ECC_INTERRUPT_ENABLE — This register is used to enable the Automotive Safety related TSO memory ECC error interrupt.
  [0] TCEIE — When set, generates an interrupt when a correctable error is detected at the DMA TSO memory interface. It is indicated in the TCES bit of DMA_ECC_Interrupt_Status register. When reset this event does not generates an interrupt.
    0=TSO memory Correctable Error Interrupt is disabled; 1=TSO memory Correctable Error Interrupt is enabled
0x1088 DMA_ECC_INTERRUPT_STATUS ro — This register indicates the Automotive Safety related TSO memory ECC error interrupt status.
  [2] TUES rw — When set, indicates that an uncorrectable error is detected at DMA TSO memory interface.
    0=DMA TSO memory Uncorrectable Error status not detected; 1=DMA TSO memory Uncorrectable Error status detected
  [1] TAMS rw — This bit when set indicates that address mismatch is found for address bus of DMA TSO memory.
    0=DMA TSO memory Address Mismatch status not detected; 1=DMA TSO memory Address Mismatch status detected
  [0] TCES rw — When set, indicates that a correctable error is detected at DMA TSO memory interface.
    0=DMA TSO memory Correctable Error status not detected; 1=DMA TSO memory Correctable Error status detected
0x1100 DMA_CH0_CONTROL — The DMA Channel n Control register specifies the MSS value for segmentation, length to skip between two descriptors, and also the features such as header splitting and 8xPBL mode.
  [24] SPH — When this bit is set, the DMA splits the header and payload in the Receive path. The DMA writes the header to the Buffer Address1 of RDES0. The DMA writes the payload to the buffer to which the Buffer Address2 is pointing. The software must ensure that the header fits into the Receive buffers. If the header length exceeds the receive buffer size, the DMA does not split the header and payload. This bit is available only if Enable Split Header Structure option is selected.
    0=Split Headers feature is disabled; 1=Split Headers feature is enabled
  [20:18] DSL — This bit specifies the Word, Dword, or Lword number (depending on the 32-bit, 64-bit, or 128-bit bus) to skip between two unchained descriptors. The address skipping starts from the end of the current descriptor to the start of the next descriptor. When the DSL value is equal to zero, the DMA takes the descriptor table as contiguous.
  [16] PBLx8 — When this bit is set, the PBL value programmed in Bits[21:16] in DMA_CH0_Tx_Control and Bits[21:16] in DMA_CH0_Rx_Control is multiplied by eight times. Therefore, the DMA transfers the data in 8, 16, 32, 64, 128, and 256 beats depending on the PBL value.
    0=8xPBL mode is disabled; 1=8xPBL mode is enabled
  [13:0] MSS — This field specifies the maximum segment size that should be used while segmenting the packet. This field is valid only if the TSE bit of DMA_CH0_Tx_Control register is set. The value programmed in this field must be more than the configured Datawidth in bytes. It is recommended to use a MSS value of 64 bytes or more.
